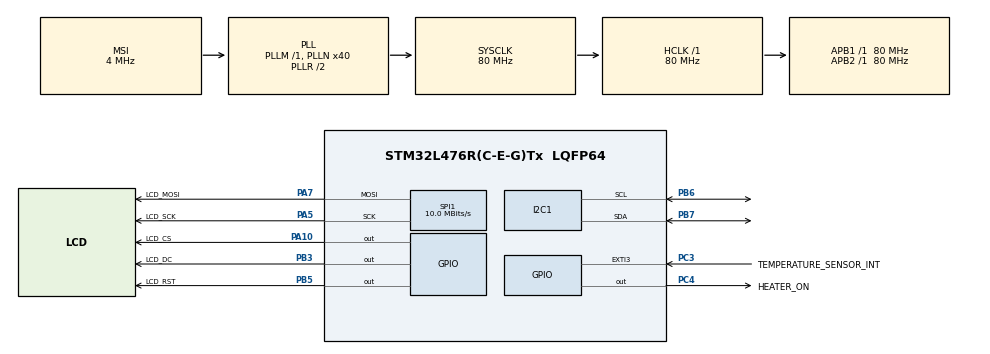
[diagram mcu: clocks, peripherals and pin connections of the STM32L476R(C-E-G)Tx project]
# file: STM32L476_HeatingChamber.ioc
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Dma.Request0=SPI1_TX
Dma.SPI1_TX.0.Direction=DMA_MEMORY_TO_PERIPH
Dma.SPI1_TX.0.Instance=DMA1_Channel3
Dma.SPI1_TX.0.MemDataAlignment=DMA_MDATAALIGN_BYTE
Dma.SPI1_TX.0.MemInc=DMA_MINC_ENABLE
Dma.SPI1_TX.0.Mode=DMA_NORMAL
Dma.SPI1_TX.0.PeriphDataAlignment=DMA_PDATAALIGN_BYTE
Dma.SPI1_TX.0.PeriphInc=DMA_PINC_DISABLE
Dma.SPI1_TX.0.Priority=DMA_PRIORITY_LOW
FREERTOS.Tasks01=defaultTask,24,128,StartDefaultTask,Default,NULL,Dynamic,NULL,NULL
FREERTOS.configTOTAL_HEAP_SIZE=24000
FREERTOS.configUSE_NEWLIB_REENTRANT=1
I2C1.Timing=0x10D19CE4
Mcu.Family=STM32L4
Mcu.Name=STM32L476R(C-E-G)Tx
Mcu.Package=LQFP64
NVIC.DMA1_Channel3_IRQn=true\:5\:0\:false\:false\:true\:true\:false\:true\:true
NVIC.EXTI3_IRQn=true\:5\:0\:false\:false\:true\:true\:true\:true\:true
NVIC.PriorityGroup=NVIC_PRIORITYGROUP_4
NVIC.TIM1_UP_TIM16_IRQn=true\:15\:0\:false\:false\:true\:false\:false\:true\:true
NVIC.TimeBase=TIM1_UP_TIM16_IRQn
NVIC.TimeBaseIP=TIM1
PA10.GPIO_Label=LCD_CS
PA10.PinState=GPIO_PIN_SET
PA10.Signal=GPIO_Output
PA13\ (JTMS-SWDIO).Mode=Serial_Wire
PA13\ (JTMS-SWDIO).Signal=SYS_JTMS-SWDIO
PA14\ (JTCK-SWCLK).Mode=Serial_Wire
PA14\ (JTCK-SWCLK).Signal=SYS_JTCK-SWCLK
PA5.GPIO_Label=LCD_SCK
PA5.Mode=TX_Only_Simplex_Unidirect_Master
PA5.Signal=SPI1_SCK
PA7.GPIO_Label=LCD_MOSI
PA7.Mode=TX_Only_Simplex_Unidirect_Master
PA7.Signal=SPI1_MOSI
PB3\ (JTDO-TRACESWO).GPIO_Label=LCD_DC
PB3\ (JTDO-TRACESWO).Signal=GPIO_Output
PB5.GPIO_Label=LCD_RST
PB5.Signal=GPIO_Output
PB6.Mode=I2C
PB6.Signal=I2C1_SCL
PB7.Mode=I2C
PB7.Signal=I2C1_SDA
PC3.GPIO_Label=TEMPERATURE_SENSOR_INT
PC3.GPIO_ModeDefaultEXTI=GPIO_MODE_IT_FALLING
PC3.GPIO_PuPd=GPIO_PULLUP
PC3.Signal=GPXTI3
PC4.GPIO_Label=HEATER_ON
PC4.GPIO_PuPd=GPIO_PULLDOWN
PC4.Signal=GPIO_Output
ProjectManager.HeapSize=0x200
ProjectManager.StackSize=0x400
ProjectManager.TargetToolchain=STM32CubeIDE
RCC.AHBFreq_Value=80000000
RCC.APB1Freq_Value=80000000
RCC.APB1TimFreq_Value=80000000
RCC.APB2Freq_Value=80000000
RCC.APB2TimFreq_Value=80000000
RCC.CortexFreq_Value=80000000
RCC.HCLKFreq_Value=80000000
RCC.HSE_VALUE=8000000
RCC.HSI_VALUE=16000000
RCC.LSE_VALUE=32768
RCC.MSI_VALUE=4000000
RCC.PLLN=40
RCC.SYSCLKFreq_VALUE=80000000
RCC.SYSCLKSource=RCC_SYSCLKSOURCE_PLLCLK
RCC.VCOOutputFreq_Value=160000000
SPI1.BaudRatePrescaler=SPI_BAUDRATEPRESCALER_8
SPI1.CalculateBaudRate=10.0 MBits/s
SPI1.DataSize=SPI_DATASIZE_8BIT
SPI1.Direction=SPI_DIRECTION_2LINES
SPI1.Mode=SPI_MODE_MASTER
SPI1.NSSPMode=SPI_NSS_PULSE_DISABLE
SPI1.VirtualType=VM_MASTER
VP_FREERTOS_VS_CMSIS_V2.Mode=CMSIS_V2
VP_RTC_VS_RTC_Activate.Mode=RTC_Enabled
VP_SYS_VS_tim1.Mode=TIM1
VP_TIM2_VS_ClockSourceINT.Mode=Internal
board=custom

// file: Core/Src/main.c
/* USER CODE BEGIN Header */
/**
  ******************************************************************************
  * @file           : main.c
  * @brief          : Main program body
  ******************************************************************************
  * @attention
  *
  * Copyright (c) 2025 STMicroelectronics.
  * All rights reserved.
  *
  * This software is licensed under terms that can be found in the LICENSE file
  * in the root directory of this software component.
  * If no LICENSE file comes with this software, it is provided AS-IS.
  *
  ******************************************************************************
  */
/* USER CODE END Header */
#include "main.h"
#include "cmsis_os.h"
#include "dma.h"
#include "i2c.h"
#include "rtc.h"
#include "spi.h"
#include "tim.h"
#include "gpio.h"

void SystemClock_Config(void);
void MX_FREERTOS_Init(void);

int main(void)
{

  /* MCU Configuration--------------------------------------------------------*/

  /* Reset of all peripherals, Initializes the Flash interface and the Systick. */
  HAL_Init();

  /* Configure the system clock */
  SystemClock_Config();

  /* Initialize all configured peripherals */
  MX_GPIO_Init();
  MX_DMA_Init();
  MX_I2C1_Init();
  MX_SPI1_Init();
  MX_TIM2_Init();
  MX_RTC_Init();

  /* Init scheduler */
  osKernelInitialize();

  /* Call init function for freertos objects (in cmsis_os2.c) */
  MX_FREERTOS_Init();

  /* Start scheduler */
  osKernelStart();

  /* We should never get here as control is now taken by the scheduler */

  /* Infinite loop */
  while (1)
  {

  }
}

void SystemClock_Config(void)
{
  RCC_OscInitTypeDef RCC_OscInitStruct = {0};
  RCC_ClkInitTypeDef RCC_ClkInitStruct = {0};

  /** Configure the main internal regulator output voltage
  */
  if (HAL_PWREx_ControlVoltageScaling(PWR_REGULATOR_VOLTAGE_SCALE1) != HAL_OK)
  {
    Error_Handler();
  }

  /** Initializes the RCC Oscillators according to the specified parameters
  * in the RCC_OscInitTypeDef structure.
  */
  RCC_OscInitStruct.OscillatorType = RCC_OSCILLATORTYPE_LSI|RCC_OSCILLATORTYPE_MSI;
  RCC_OscInitStruct.LSIState = RCC_LSI_ON;
  RCC_OscInitStruct.MSIState = RCC_MSI_ON;
  RCC_OscInitStruct.MSICalibrationValue = 0;
  RCC_OscInitStruct.MSIClockRange = RCC_MSIRANGE_6;
  RCC_OscInitStruct.PLL.PLLState = RCC_PLL_ON;
  RCC_OscInitStruct.PLL.PLLSource = RCC_PLLSOURCE_MSI;
  RCC_OscInitStruct.PLL.PLLM = 1;
  RCC_OscInitStruct.PLL.PLLN = 40;
  RCC_OscInitStruct.PLL.PLLP = RCC_PLLP_DIV7;
  RCC_OscInitStruct.PLL.PLLQ = RCC_PLLQ_DIV2;
  RCC_OscInitStruct.PLL.PLLR = RCC_PLLR_DIV2;
  if (HAL_RCC_OscConfig(&RCC_OscInitStruct) != HAL_OK)
  {
    Error_Handler();
  }

  /** Initializes the CPU, AHB and APB buses clocks
  */
  RCC_ClkInitStruct.ClockType = RCC_CLOCKTYPE_HCLK|RCC_CLOCKTYPE_SYSCLK
                              |RCC_CLOCKTYPE_PCLK1|RCC_CLOCKTYPE_PCLK2;
  RCC_ClkInitStruct.SYSCLKSource = RCC_SYSCLKSOURCE_PLLCLK;
  RCC_ClkInitStruct.AHBCLKDivider = RCC_SYSCLK_DIV1;
  RCC_ClkInitStruct.APB1CLKDivider = RCC_HCLK_DIV1;
  RCC_ClkInitStruct.APB2CLKDivider = RCC_HCLK_DIV1;

  if (HAL_RCC_ClockConfig(&RCC_ClkInitStruct, FLASH_LATENCY_4) != HAL_OK)
  {
    Error_Handler();
  }
}

void HAL_TIM_PeriodElapsedCallback(TIM_HandleTypeDef *htim)
{
  if (htim->Instance == TIM1) {
    HAL_IncTick();
  }
}

void Error_Handler(void)
{
  __disable_irq();
  while (1)
  {
  }
}

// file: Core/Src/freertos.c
/* USER CODE BEGIN Header */
/**
  ******************************************************************************
  * File Name          : freertos.c
  * Description        : Code for freertos applications
  ******************************************************************************
  * @attention
  *
  * Copyright (c) 2025 STMicroelectronics.
  * All rights reserved.
  *
  * This software is licensed under terms that can be found in the LICENSE file
  * in the root directory of this software component.
  * If no LICENSE file comes with this software, it is provided AS-IS.
  *
  ******************************************************************************
  */
/* USER CODE END Header */

#include "FreeRTOS.h"
#include "task.h"
#include "main.h"
#include "cmsis_os.h"

/* USER CODE BEGIN Includes */

#include "i2c.h"
#include "temperature_sensor.h"
#include "display.h"
#include "heater.h"
#include "rtc_module.h"
#include "charts.h"

/* USER CODE END Includes */

/* USER CODE BEGIN Variables */

float temperature = 0.0f;

/* USER CODE END Variables */
/* Definitions for defaultTask */
osThreadId_t defaultTaskHandle;
const osThreadAttr_t defaultTask_attributes = {
  .name = "defaultTask",
  .stack_size = 128 * 4,
  .priority = (osPriority_t) osPriorityNormal,
};

void StartDefaultTask(void *argument);

void MX_FREERTOS_Init(void); /* (MISRA C 2004 rule 8.1) */

void MX_FREERTOS_Init(void) {

  /* Create the thread(s) */
  /* creation of defaultTask */
  defaultTaskHandle = osThreadNew(StartDefaultTask, NULL, &defaultTask_attributes);

}

void StartDefaultTask(void *argument)
{
  /* USER CODE BEGIN StartDefaultTask */
	temperature_sensor_init();
	rtc_init();
	display_init();
	heater_init();
	charts_init();

  /* Infinite loop */
  for(;;)
  {
	 /* if(temperature_sensor_is_alarm_triggered())
	  {
		 // heater_turn_off();
	  }*/

      osDelay(100);
  }
  /* USER CODE END StartDefaultTask */
}
